# Port_J_3 register map
Vendor: Texas Instruments
Peripheral module from a debugger description file (folder msp430).
Registers are 16-bit, read-write, reset 0x0 unless marked. A register's access mark holds for its fields unless they carry their own. Offsets are as the file gives them; lines under a group give offsets from that group; [hi:lo] are bit positions; {n}, {i} and the like mark numbered series; 'fields as' and 'values as' point back to an identical list; <NAME> marks a mode.

## Port_J
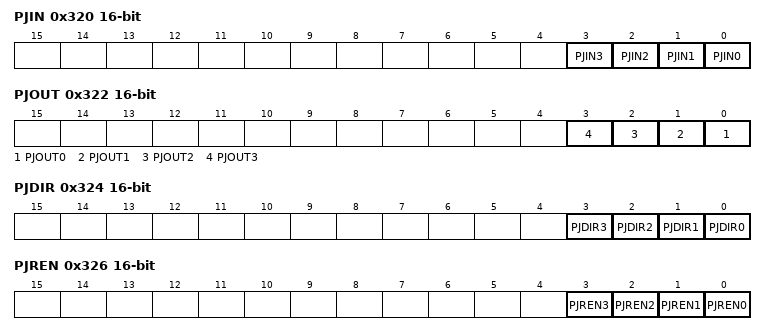
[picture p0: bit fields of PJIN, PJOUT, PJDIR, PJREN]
0x320 PJIN — Port J Input
  [n] PJIN{n} (n=0..3)
0x322 PJOUT — Port J Output
  [n] PJOUT{n} (n=0..3)
0x324 PJDIR — Port J Direction
  [n] PJDIR{n} (n=0..3)
0x326 PJREN — Port J Resistor Enable
  [n] PJREN{n} (n=0..3)
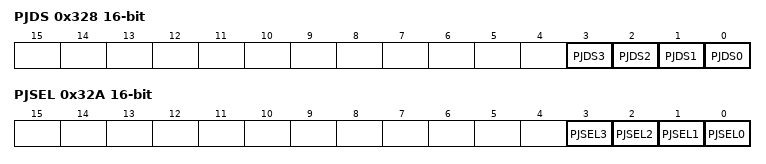
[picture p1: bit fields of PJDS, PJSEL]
0x328 PJDS — Port J Drive Strenght
  [n] PJDS{n} (n=0..3)
0x32A PJSEL — Port J Selection
  [n] PJSEL{n} (n=0..3)
